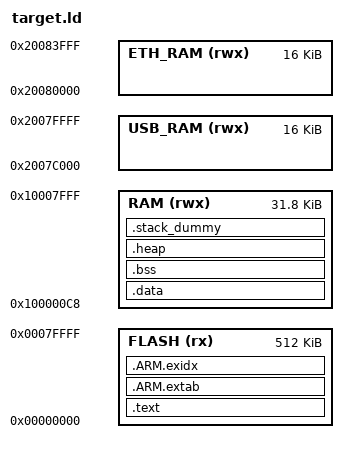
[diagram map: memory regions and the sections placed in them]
/* Linker script for mbed LPC1768 */
GROUP(
 libgcc.a
 libc.a
 libstdc++.a
 libm.a
 /*libcr_newlib_nohost.a*/
 crti.o
 crtn.o
 crtbegin.o
 crtend.o
 )


/* Linker script to configure memory regions. */
MEMORY
{
  FLASH (rx) : ORIGIN = 0x00000000, LENGTH = 512K
  RAM (rwx) : ORIGIN = 0x100000C8, LENGTH = 0x7F38

  USB_RAM(rwx) : ORIGIN = 0x2007C000, LENGTH = 16K
  ETH_RAM(rwx) : ORIGIN = 0x20080000, LENGTH = 16K
}

__ETHRAM_segment_start__  = ORIGIN( ETH_RAM );
/* This marks the highest allocatable stack space */
__stacks_min__ = ORIGIN( ETH_RAM ) + LENGTH( ETH_RAM );

/* Linker script to place sections and symbol values. Should be used together
 * with other linker script that defines memory regions FLASH and RAM.
 * It references following symbols, which must be defined in code:
 *   Reset_Handler : Entry of reset handler
 * 
 * It defines following symbols, which code can use without definition:
 *   __exidx_start
 *   __exidx_end
 *   __etext
 *   __data_start__
 *   __preinit_array_start
 *   __preinit_array_end
 *   __init_array_start
 *   __init_array_end
 *   __fini_array_start
 *   __fini_array_end
 *   __data_end__
 *   __bss_start__
 *   __bss_end__
 *   __end__
 *   end
 *   __HeapLimit
 *   __StackLimit
 *   __StackTop
 *   __stack
 */
ENTRY(Reset_Handler)

SECTIONS
{
    .text :
    {
        KEEP(*(.isr_vector))
        *(.text*)

        KEEP(*(.init))
        KEEP(*(.fini))

        /* .ctors */
        *crtbegin.o(.ctors)
        *crtbegin?.o(.ctors)
        *(EXCLUDE_FILE(*crtend?.o *crtend.o) .ctors)
        *(SORT(.ctors.*))
        *(.ctors)

        /* .dtors */
        *crtbegin.o(.dtors)
        *crtbegin?.o(.dtors)
        *(EXCLUDE_FILE(*crtend?.o *crtend.o) .dtors)
        *(SORT(.dtors.*))
        *(.dtors)

        *(SORT(.rodata*))

        KEEP(*(.eh_frame*))
    } > FLASH

    .ARM.extab : 
    {
        *(.ARM.extab* .gnu.linkonce.armextab.*)
    } > FLASH

    __exidx_start = .;
    .ARM.exidx :
    {
        *(.ARM.exidx* .gnu.linkonce.armexidx.*)
    } > FLASH
    __exidx_end = .;

    __etext = .;
        
    .data : AT (__etext)
    {
        __data_start__ = .;
        *(vtable)
        *(.data*)

	/* this magic is needed for the device tables of openMRN */
        . = ALIGN (8);
        KEEP(*( SORT (.device.table.*))) ;

        . = ALIGN(4);
        /* preinit data */
        PROVIDE (__preinit_array_start = .);
        KEEP(*(.preinit_array))
        PROVIDE (__preinit_array_end = .);

        . = ALIGN(4);
        /* init data */
        PROVIDE (__init_array_start = .);
        KEEP(*(SORT(.init_array.*)))
        KEEP(*(.init_array))
        PROVIDE (__init_array_end = .);


        . = ALIGN(4);
        /* finit data */
        PROVIDE (__fini_array_start = .);
        KEEP(*(SORT(.fini_array.*)))
        KEEP(*(.fini_array))
        PROVIDE (__fini_array_end = .);

        . = ALIGN(4);
        /* All data end */
        __data_end__ = .;

    } > RAM

    __data_init_start__ = LOADADDR( .data ) ;
    ASSERT(__data_init_start__ == __etext, "Initialized data source inconsistent")
        

    .bss :
    {
        __bss_start__ = .;
        *(.bss*)
        *(COMMON)
        __bss_end__ = .;
    } > RAM
    
    .heap :
    {
        __end__ = .;
        end = __end__;
        *(.heap*)
        __HeapLimit = .;
        __cs3_heap_start = .;
    } > RAM

    /* .stack_dummy section doesn't contains any symbols. It is only
     * used for linker to calculate size of stack sections, and assign
     * values to stack symbols later */
    .stack_dummy :
    {
        *(.stack)
    } > RAM

    /* Set stack top to end of RAM, and stack limit move down by
     * size of stack_dummy section */
    __StackTop = ORIGIN(RAM) + LENGTH(RAM);
    __StackLimit = __StackTop - SIZEOF(.stack_dummy);
    __cs3_heap_end = __StackLimit;
    PROVIDE(__stack = __StackTop);
    
    /* Check if data + heap + stack exceeds RAM limit */
    ASSERT(__StackLimit >= __HeapLimit, "region RAM overflowed with stack")
}
